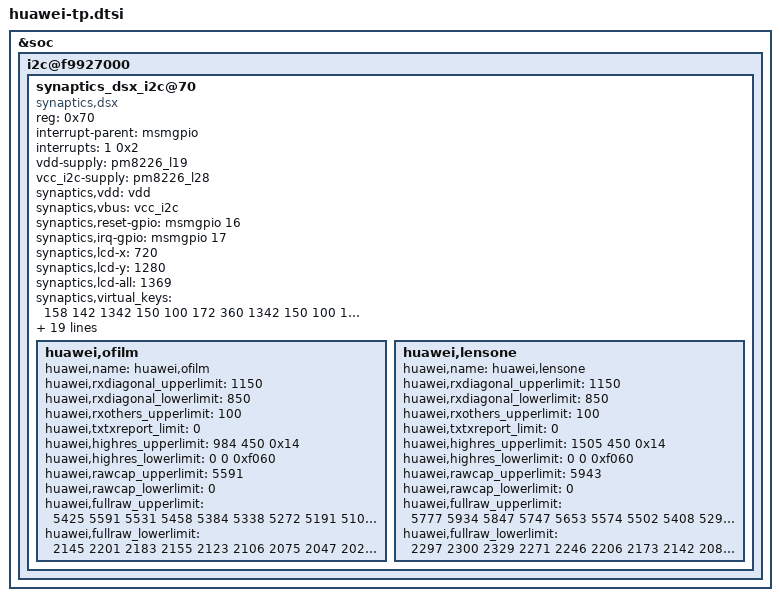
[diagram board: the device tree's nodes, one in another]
/* modify the lcd size and capacitance limit for H892L first*/
/*Modified the virtual key width and x coordinate*/
&soc{
	i2c@f9927000 {
		status = "ok";
		synaptics_dsx_i2c@70 {
			compatible = "synaptics,dsx";
			reg = <0x70>;
			interrupt-parent = <&msmgpio>;
			interrupts = <1 0x2>;
			vdd-supply = <&pm8226_l19>;
			vcc_i2c-supply = <&pm8226_l28>;
			synaptics,vdd = "vdd";
			synaptics,vbus = "vcc_i2c";
			synaptics,reset-gpio = <&msmgpio 16 0x00>;
			synaptics,irq-gpio = <&msmgpio 17 0x00>;

			synaptics,lcd-x = <720>;
			synaptics,lcd-y = <1280>;
			synaptics,lcd-all = <1369>;
			synaptics,virtual_keys = /* KeyCode CenterX CenterY Width Height */
				/* KEY_BACK */
				<158 142 1342 150 100
				/* KEY_HOMEPAGE instead of KEY_HOME(102) */
				172 360 1342 150 100
				/* KEY_MENU */
				139 578 1342 150 100>;
			/* SYNAPTICS_WAKE_UP_GESTURE_FLAG:'1'->enabled,'0'->disabled */
			/*IC flash is not enough for holster,so del one gesture*/
			synaptics,gesture_enabled = <0>;
			/* Gestures that supported:                           */
			/* bit0  Double tap                                        */
			/* bit1  Single finger slide from left to right     */
			/* bit2  Single finger slide from right to left     */
			/* bit3  Single finger slide from top to bottom  */
			/* bit4  Single finger slide from bottom to top  */
			/* bit5  Double finger slide from top to bottom--disable for holster*/
			/* bit6  Single finger slide circle                     */
			/* bit7  Single finger write letter c                  */
			/* bit8  Single finger write letter e                  */
			/* bit9  Single finger write letter m                 */
			/* bit10 Single finger write letter w                 */
			/* bit11 Palm off screen                                */
			synaptics,easy_wakeup_supported_gestures = <0>;

			/*Defination of report key value  for different gestures*/
			synaptics,easy_wakeup_gesture_keys = 
			<	59 /*0.Double tap:KEY_F1*/
				60 /*1.Single finger slide from left to right*/
				61 /*2.Single finger slide from right to left:KEY_F3*/
				62 /*3.Single finger slide from top to bottom*/
				63 /*4.Single finger slide from bottom to top:KEY_F5*/
				64 /*5.Double finger slide from top to bottom*/
				65 /*6.Single finger slide circle:KEY_F7*/
				66 /*7.Single finger write letter c*/
				67 /*8.Single finger write letter e:KEY_F9*/
				68 /*9.Single finger write letter m*/
				87 /*10.Single finger write letter w:KEY_F11*/
				88 /*11.Palm off screen*/
			>;
			/* Double-tap-zone defined by huawei */
			/* Shielded area is:1cm left,1cm right,3cm up,2cm down */
			huawei,dtz_x0 = <87>;
			huawei,dtz_y0 = <262>;
			huawei,dtz_x1 = <453>;
			huawei,dtz_y1 = <785>;
			synaptics,grip_algorithm_supported = <1>;
			synaptics,grip_algorithm_enabled = <1>;
			huawei,grip_left_lsb = <0x32>;
			huawei,grip_left_msb = <0x0>;
			huawei,grip_right_lsb = <0x1A>;
			huawei,grip_right_msb = <0x04>;

			/*del the synaptics,glove_enabled,because H892L have no this function*/
			synaptics,reset-on-status = <0>;
			synaptics,power-delay-ms = <160>;
			synaptics,reset-delay-ms = <100>;
			synaptics,reset-active-ms = <90>;
			/*Use to combine fw name*/
			synaptics,product_name = "h892L";
			/*capacitance self-adapt*/
			huawei,ofilm {
				huawei,name = "huawei,ofilm";
				huawei,rxdiagonal_upperlimit = <1150>;
				huawei,rxdiagonal_lowerlimit = <850>;
				huawei,rxothers_upperlimit = <100>;
				huawei,txtxreport_limit = <0>;
				huawei,highres_upperlimit = <984 450 0x14>;/*0x14=20*/
				huawei,highres_lowerlimit = <0 0 0xf060>;/*0xf060=-4000*/
				huawei,rawcap_upperlimit = <5591>;
				huawei,rawcap_lowerlimit = <0>;

				huawei,fullraw_upperlimit =
					<5425 5591 5531 5458 5384 5338 5272 5191 5108 5027 4984 4902 4841 4131 4072 4093 3964 3957 3882 3907 3815 3838 3732 3728 3585 9999
					5268 5405 5338 5257 5184 5110 5058 4972 4883 4802 4760 4685 4617 4107 4037 4057 3931 3924 3840 3868 3777 3791 3696 3704 3693 3663
					5264 5367 5297 5198 5124 5056 4982 4904 4827 4736 4694 4615 4530 4128 4058 4065 3949 3941 3859 3889 3801 3819 3711 3715 3708 3914
					5222 5341 5252 5150 5068 5003 4939 4848 4764 4687 4634 4566 4470 4156 4079 4100 3977 3967 3892 3920 3833 3850 3742 3749 3742 3962
					5196 5320 5222 5108 5037 4944 4886 4797 4718 4632 4583 4513 4419 4180 4114 4127 4016 4011 3915 3950 3862 3886 3771 3791 3774 3980
					5168 5269 5177 5070 4985 4895 4841 4750 4664 4578 4531 4466 4362 4211 4130 4152 4048 4040 3949 3983 3893 3914 3805 3836 3813 4015
					5128 5222 5138 5035 4946 4858 4783 4705 4622 4530 4481 4419 4306 4246 4165 4177 4076 4075 3995 4025 3943 3964 3850 3883 3862 4044
					5111 5202 5108 4998 4912 4825 4746 4659 4585 4498 4445 4369 4264 4306 4202 4219 4117 4123 4046 4076 3994 4019 3899 3934 3910 4088
					5104 5196 5101 4985 4894 4796 4718 4634 4564 4474 4418 4355 4228 4356 4261 4281 4176 4179 4113 4137 4054 4076 3969 4009 3988 4159
					5097 5198 5105 4979 4874 4775 4702 4618 4540 4445 4396 4321 4202 4396 4510 4338 4229 4236 4167 4200 4110 4130 4025 4068 4054 4204
					5083 5168 5087 4967 4867 4764 4688 4592 4516 4433 4382 4313 4188 4454 4376 4403 4303 4299 4236 4264 4183 4198 4106 4141 4128 4268
					5063 5152 5073 4951 4860 4758 4683 4573 4505 4421 4369 4291 4172 4531 4450 4474 4375 4375 4323 4348 4264 4279 4186 4223 4200 4312
					5059 5136 5063 4946 4852 4757 4674 4568 4478 4394 4355 4274 4152 4606 4529 4550 4460 4459 4400 4435 4345 4363 4278 4321 4289 4110
					5093 5178 5091 4998 4887 4786 4701 4600 4499 4421 4376 4306 4172 4999 4887 4894 4785 4782 4715 4733 4648 4667 4578 4607 4442 9999>;

				huawei,fullraw_lowerlimit =
					<2145 2201 2183 2155 2123 2106 2075 2047 2021 1994 1965 1951 1928 1640 1603 1619 1577 1561 1529 1539 1499 1500 1456 1476 1390 0
					2099 2145 2118 2087 2051 2030 2000 1978 1943 1919 1890 1874 1845 1632 1596 1611 1572 1552 1518 1527 1489 1489 1445 1468 1434 1459
					2084 2127 2100 2069 2036 2012 1980 1950 1889 1899 1865 1850 1817 1640 1601 1613 1575 1556 1524 1530 1494 1491 1451 1473 1439 1570
					2075 2115 2088 2053 2022 1990 1959 1934 1865 1873 1839 1824 1791 1650 1613 1627 1588 1569 1538 1542 1505 1506 1467 1487 1454 1582
					2061 2103 2072 2037 2001 1975 1942 1917 1845 1851 1818 1805 1773 1667 1626 1637 1600 1578 1551 1553 1520 1523 1482 1501 1470 1586
					2047 2089 2061 2025 1988 1958 1922 1899 1824 1834 1800 1778 1749 1668 1631 1646 1610 1588 1562 1564 1534 1535 1497 1515 1483 1594
					2035 2074 2045 2004 1970 1941 1908 1882 1802 1813 1781 1762 1727 1679 1641 1661 1625 1603 1578 1579 1548 1548 1513 1533 1501 1607
					2027 2062 2034 1994 1956 1928 1888 1865 1785 1798 1764 1746 1707 1703 1672 1684 1647 1628 1604 1602 1568 1573 1536 1561 1527 1623
					2025 2057 2029 1991 1950 1923 1886 1854 1782 1791 1754 1734 1700 1725 1691 1706 1672 1654 1626 1626 1593 1598 1565 1588 1556 1647
					2015 2047 2015 1981 1938 1912 1880 1844 1770 1779 1746 1722 1684 1749 1710 1727 1697 1678 1649 1648 1617 1622 1590 1613 1578 1664
					2008 2044 2008 1972 1932 1907 1871 1838 1760 1767 1736 1712 1673 1775 1736 1751 1725 1702 1674 1672 1641 1647 1617 1640 1607 1691
					2003 2040 2006 1968 1930 1906 1867 1837 1752 1766 1727 1709 1666 1805 1767 1779 1752 1734 1705 1704 1676 1683 1655 1673 1643 1713
					2000 2032 2003 1964 1923 1898 1859 1830 1745 1757 1721 1701 1659 1841 1801 1815 1785 1767 1742 1737 1712 1716 1689 1709 1677 1621
					2009 2040 2021 1970 1932 1899 1865 1834 1750 1762 1723 1709 1667 1985 1938 1945 1903 1889 1857 1853 1825 1828 1803 1818 1750 0>;
			};
			huawei,lensone {
				huawei,name = "huawei,lensone";
				huawei,rxdiagonal_upperlimit = <1150>;
				huawei,rxdiagonal_lowerlimit = <850>;
				huawei,rxothers_upperlimit = <100>;
				huawei,txtxreport_limit = <0>;
				huawei,highres_upperlimit = <1505 450 0x14>;/*0x14=20*/
				huawei,highres_lowerlimit = <0 0 0xf060>;/*0xf060=-4000*/
				huawei,rawcap_upperlimit = <5943>;
				huawei,rawcap_lowerlimit = <0>;

				huawei,fullraw_upperlimit =
					<5777 5934 5847 5747 5653 5574 5502 5408 5296 5240 5140 5034 4977 3945 3938 3855 3738 3718 3616 3700 3537 3537 3453 3472 3280 9999 
					5558 5658 5572 5465 5378 5296 5224 5132 5027 4972 4883 4788 4720 3966 3924 3864 3768 3714 3649 3722 3539 3536 3479 3516 3526 3539
					5503 5601 5500 5395 5293 5202 5132 5034 4915 4853 4753 4645 4575 3970 3907 3843 3752 3746 3624 3697 3550 3525 3448 3490 3507 3777
					5602 5712 5601 5479 5369 5264 5191 5083 4949 4880 4769 4657 4568 4044 4020 3938 3833 3816 3700 3777 3610 3606 3514 3557 3533 3683
					5607 5713 5598 5475 5355 5245 5167 5056 4914 4845 4729 4607 4505 4097 4076 3995 3882 3844 3752 3836 3669 3665 3568 3609 3570 3740
					5495 5587 5453 5335 5220 5112 5027 4918 4778 4706 4590 4470 4368 4089 4053 3978 3878 3873 3752 3831 3662 3661 3585 3621 3655 3890
					5314 5367 5258 5129 5017 4915 4844 4734 4600 4544 4426 4303 4204 4064 4009 3964 3871 3852 3750 3829 3669 3651 3600 3640 3687 3955
					5355 5434 5303 5163 5047 4944 4859 4744 4603 4534 4415 4288 4183 4166 4125 4060 3966 3950 3850 3918 3745 3740 3687 3728 3739 3934
					5453 5532 5395 5240 5117 5012 4922 4803 4646 4566 4436 4314 4180 4317 4272 4193 4092 4103 3960 4037 3880 3876 3796 3830 3834 3875
					5430 5506 5366 5220 5094 4984 4890 4776 4614 4534 4401 4277 4134 4375 4347 4275 4169 4166 4043 4118 3964 3966 3882 3910 3906 3995
					5322 5391 5257 5108 4975 4872 4786 4671 4515 4439 4307 4163 4044 4396 4345 4302 4209 4184 4092 4169 3998 3990 3938 3980 3981 4172
					5198 5227 5098 4960 4837 4732 4650 4750 4391 4321 4195 4074 3955 4424 4365 4316 4240 4247 4124 4202 4040 4029 3978 4020 4078 4288
					5287 5325 5191 5054 4909 4797 4709 4594 4440 4359 4233 4128 3995 4575 4541 4480 4390 4386 4289 4369 4200 4200 4138 4174 4148 3955
					5401 5455 5317 5160 5021 4902 4809 4690 4522 4442 4310 4204 4048 4989 4943 4880 4765 4765 4666 4753 4582 4582 4489 4517 4277 9999>;

				huawei,fullraw_lowerlimit =
					<2297 2300 2329 2271 2246 2206 2173 2142 2089 2062 2032 1995 1958 1544 1507 1479 1443 1450 1392 1409 1365 1358 1322 1340 1144 0
					2200 2228 2207 2160 2136 2094 2064 2026 1986 1956 1927 1892 1853 1552 1525 1511 1451 1458 1411 1415 1371 1371 1337 1351 1229 1373
					2185 2187 2177 2145 2105 2066 2033 1995 1946 1901 1878 1852 1809 1550 1525 1502 1452 1448 1404 1405 1371 1369 1326 1349 1220 1461
					2225 2232 2218 2184 2132 2094 2049 2010 1947 1914 1880 1851 1805 1583 1548 1537 1488 1479 1425 1431 1400 1397 1349 1377 1238 1437
					2218 2223 2215 2163 2123 2068 2032 1984 1935 1898 1857 1825 1775 1602 1574 1562 1500 1500 1449 1455 1415 1406 1374 1389 1259 1449
					2169 2164 2158 2099 2061 2010 1977 1933 1875 1841 1800 1768 1715 1611 1574 1563 1503 1506 1457 1457 1424 1408 1388 1398 1275 1512
					2105 2092 2073 2028 1992 1934 1901 1851 1809 1770 1739 1704 1655 1593 1562 1559 1509 1504 1448 1463 1428 1423 1395 1412 1296 1544
					2121 2081 2094 2057 2005 1957 1916 1871 1814 1763 1742 1707 1646 1642 1603 1597 1547 1542 1488 1503 1466 1457 1428 1450 1327 1535
					2163 2156 2126 2086 2031 1983 1937 1880 1840 1779 1742 1704 1644 1692 1664 1650 1590 1594 1545 1554 1515 1508 1475 1491 1361 1513
					2155 2148 2119 2076 2026 1968 1926 1874 1816 1768 1728 1680 1620 1716 1686 1679 1622 1625 1566 1579 1547 1531 1516 1521 1387 1554
					2106 2096 2074 2015 1967 1905 1875 1825 1767 1726 1694 1646 1580 1737 1697 1699 1644 1628 1589 1607 1571 1550 1536 1550 1424 1634
					2054 2040 2006 1971 1922 1862 1828 1775 1724 1676 1644 1599 1542 1728 1710 1692 1652 1649 1615 1609 1590 1580 1565 1557 1470 1666
					2084 2069 2039 2007 1947 1898 1846 1800 1736 1685 1652 1604 1538 1800 1764 1763 1707 1711 1656 1664 1647 1640 1623 1633 1611 1547
					2123 2108 2096 2051 1964 1826 1762 1726 1672 1608 1572 1497 1466 1861 1820 1821 1746 1747 1722 1728 1700 1691 1632 1670 1595 0>;
			};
		};
	};
};
